# STM32G473 register map
File version: 2.8
CPU: CM4 r0p1, little endian, MPU, FPU, 4 interrupt priority bits
Registers are 32-bit, read-write, reset 0x0 unless marked. A register's access mark holds for its fields unless they carry their own. Offsets are from the block's base; [hi:lo] are bit positions; {n}, {i} and the like mark numbered series; 'fields as' and 'values as' point back to an identical list.

## RCC — Reset and clock control
Base 0x40021000
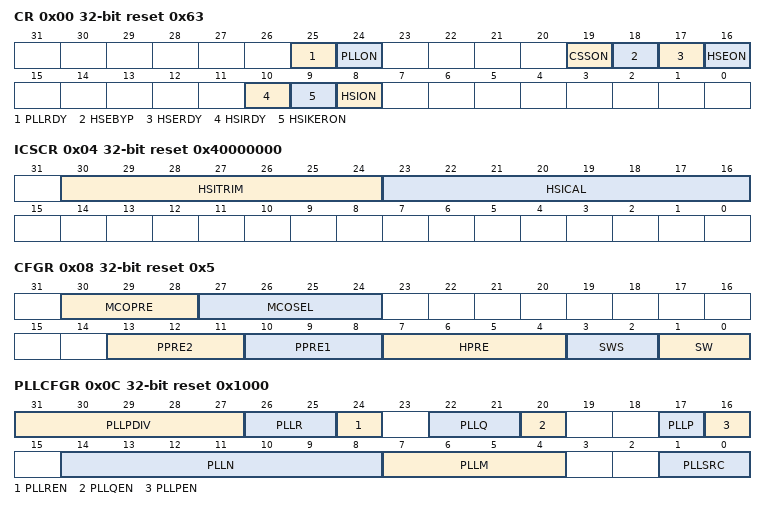
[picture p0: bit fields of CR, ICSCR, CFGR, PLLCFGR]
0x00 CR access per field reset 0x63 — Clock control register
  [25] PLLRDY ro — Main PLL clock ready flag
    0=NotReady (Clock not ready); 1=Ready (Clock ready)
  [24] PLLON rw — Main PLL enable
    0=Off (Clock Off); 1=On (Clock On)
  [19] CSSON rw — Clock security system enable
    0=Off (Clock security system disabled (clock detector OFF)); 1=On (Clock security system enable (clock detector ON if the HSE is ready, OFF if not))
  [18] HSEBYP rw — HSE crystal oscillator bypass
    0=NotBypassed (HSE crystal oscillator not bypassed); 1=Bypassed (HSE crystal oscillator bypassed with external clock)
  [17] HSERDY ro — HSE clock ready flag
    0=NotReady (Clock not ready); 1=Ready (Clock ready)
  [16] HSEON rw — HSE clock enable
    0=Off (Clock Off); 1=On (Clock On)
  [10] HSIRDY ro — HSI16 clock ready flag
    0=NotReady (Clock not ready); 1=Ready (Clock ready)
  [9] HSIKERON rw — HSI16 always enable for peripheral kernels.
  [8] HSION rw — HSI16 clock enable
    0=Off (Clock Off); 1=On (Clock On)
0x04 ICSCR access per field reset 0x40000000 — Internal clock sources calibration register
  [30:24] HSITRIM rw — HSI16 clock trimming
  [23:16] HSICAL ro — HSI16 clock calibration
0x08 CFGR access per field reset 0x5 — Clock configuration register
  [30:28] MCOPRE rw — Microcontroller clock output prescaler
    0=Div1 (MCO divided by 1); 1=Div2 (MCO divided by 2); 2=Div4 (MCO divided by 4); 3=Div8 (MCO divided by 8); 4=Div16 (MCO divided by 16)
  [27:24] MCOSEL rw — Microcontroller clock output
    0=None (MCO output disabled, no clock on MCO); 1=SYSCLK (SYSCLK system clock selected); 2=MSI (MSI clock selected); 3=HSI (HSI clock selected); 4=HSE (HSE clock selected); 5=PLL (Main PLL clock selected); 6=LSI (LSI clock selected); 7=LSE (LSE clock selected); 8=HSI48 (Internal HSI48 clock selected)
  [13:11] PPRE2 rw — APB2 prescaler
    4=Div2 (HCLK divided by 2); 5=Div4 (HCLK divided by 4); 6=Div8 (HCLK divided by 8); 7=Div16 (HCLK divided by 16); other=Div1 (HCLK not divided)
  [10:8] PPRE1 rw — APB1 prescaler
    values as PPRE2
  [7:4] HPRE rw — AHB prescaler
    8=Div2 (SYSCLK divided by 2); 9=Div4 (SYSCLK divided by 4); 10=Div8 (SYSCLK divided by 8); 11=Div16 (SYSCLK divided by 16); 12=Div64 (SYSCLK divided by 64); 13=Div128 (SYSCLK divided by 128); 14=Div256 (SYSCLK divided by 256); 15=Div512 (SYSCLK divided by 512); other=Div1 (SYSCLK not divided)
  [3:2] SWS ro — System clock switch status
    0=MSI (MSI oscillator used as system clock); 1=HSI (HSI oscillator used as system clock); 2=HSE (HSE used as system clock); 3=PLL (PLL used as system clock)
  [1:0] SW rw — System clock switch
    0=MSI (MSI selected as system clock); 1=HSI (HSI selected as system clock); 2=HSE (HSE selected as system clock); 3=PLL (PLL selected as system clock)
0x0C PLLCFGR reset 0x1000 — PLL configuration register
  [31:27] PLLPDIV — Main PLLP division factor
    0=PLLP (pll_p_ck is controlled by PLLP); {v}=Div{v} (pll_p_ck = vco_ck / {v}) (v=2..31)
  [26:25] PLLR — Main PLL division factor for PLL R clock (system clock)
    0=Div2 (pll_r_ck = vco_ck / 2); 1=Div4 (pll_r_ck = vco_ck / 4); 2=Div6 (pll_r_ck = vco_ck / 6); 3=Div8 (pll_r_ck = vco_ck / 8)
  [24] PLLREN — PLL R clock output enable
  [22:21] PLLQ — Main PLL division factor for PLL Q clock.
    0=Div2 (pll_q_ck = vco_ck / 2); 1=Div4 (pll_q_ck = vco_ck / 4); 2=Div6 (pll_q_ck = vco_ck / 6); 3=Div8 (pll_q_ck = vco_ck / 8)
  [20] PLLQEN — Main PLL Q clock output enable
  [17] PLLP — Main PLL division factor for PLL P clock.
    0=Div7 (pll_p_ck = vco_ck / 7); 1=Div17 (pll_p_ck = vco_ck / 17)
  [16] PLLPEN — Main PLL PLL P clock output enable
  [14:8] PLLN — Main PLL multiplication factor for VCO
    {v}=Div{v} (pll_n_ck = vco_ck / {v}) (v=8..127)
  [7:4] PLLM — Division factor for the main PLL input clock
    {v}=Div{v+1} (pll_p_ck = vco_ck / {v+1}) (v=0..15)
  [1:0] PLLSRC — Main PLL entry clock source
    0=None (No clock sent to PLL); 2=HSI16 (HSI16 sent to PLL input); 3=HSE (HSE sent to PLL input)
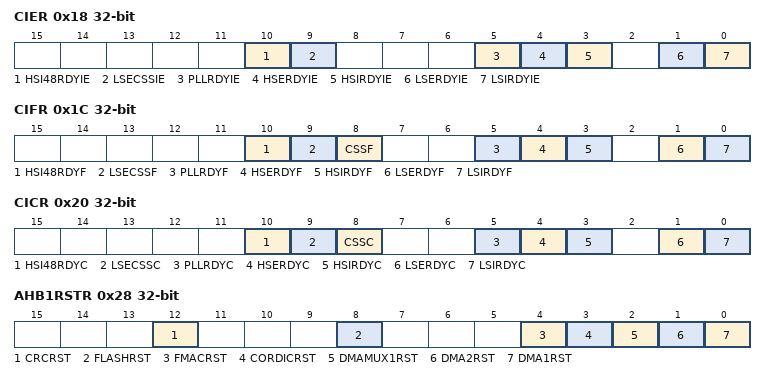
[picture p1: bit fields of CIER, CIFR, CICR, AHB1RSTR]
0x18 CIER — Clock interrupt enable register
  [10] HSI48RDYIE — HSI48 ready interrupt enable
  [9] LSECSSIE — LSE clock security system interrupt enable
  [5] PLLRDYIE — PLL ready interrupt enable
  [4] HSERDYIE — HSE ready interrupt enable
  [3] HSIRDYIE — HSI16 ready interrupt enable
  [1] LSERDYIE — LSE ready interrupt enable
  [0] LSIRDYIE — LSI ready interrupt enable
0x1C CIFR ro — Clock interrupt flag register
  [10] HSI48RDYF — HSI48 ready interrupt flag
  [9] LSECSSF — LSE Clock security system interrupt flag
  [8] CSSF — Clock security system interrupt flag
  [5] PLLRDYF — PLL ready interrupt flag
  [4] HSERDYF — HSE ready interrupt flag
  [3] HSIRDYF — HSI16 ready interrupt flag
  [1] LSERDYF — LSE ready interrupt flag
  [0] LSIRDYF — LSI ready interrupt flag
0x20 CICR wo — Clock interrupt clear register
  [10] HSI48RDYC — HSI48 oscillator ready interrupt clear
  [9] LSECSSC — LSE Clock security system interrupt clear
  [8] CSSC — Clock security system interrupt clear
  [5] PLLRDYC — PLL ready interrupt clear
  [4] HSERDYC — HSE ready interrupt clear
  [3] HSIRDYC — HSI16 ready interrupt clear
  [1] LSERDYC — LSE ready interrupt clear
  [0] LSIRDYC — LSI ready interrupt clear
0x28 AHB1RSTR — AHB1 peripheral reset register
  [all] fields
    1=Reset the selected module
  [12] CRCRST — CRC reset
  [8] FLASHRST — Flash memory interface reset
  [4] FMACRST — Set and cleared by software
  [3] CORDICRST — Set and cleared by software
  [2] DMAMUX1RST — Set and cleared by software.
  [1] DMA2RST — DMA2 reset
  [0] DMA1RST — DMA1 reset
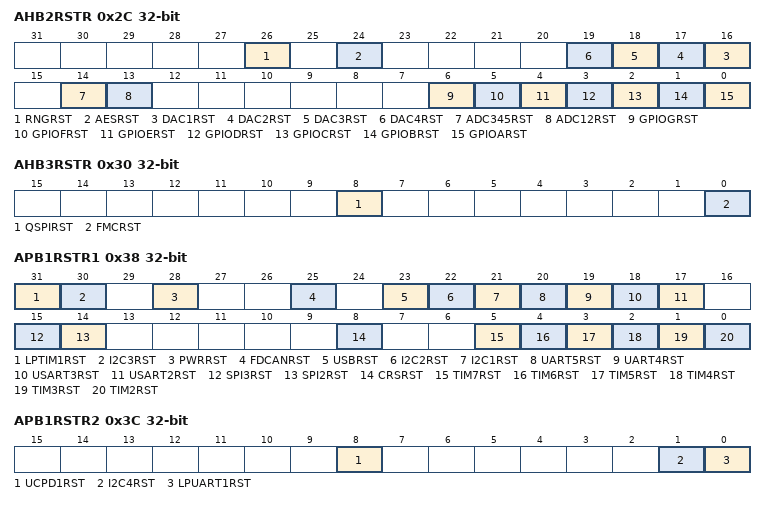
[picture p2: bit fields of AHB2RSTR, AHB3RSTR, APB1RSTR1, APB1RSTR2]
0x2C AHB2RSTR — AHB2 peripheral reset register
  [all] fields
    1=Reset the selected module
  [26] RNGRST — RNG reset
  [24] AESRST — AESRST reset
  [n+15] DAC{n}RST (n=1..4) — DAC{n} reset
  [14] ADC345RST — ADC345 reset
  [13] ADC12RST — ADC12 reset
  [6] GPIOGRST — IO port G reset
  [5] GPIOFRST — IO port F reset
  [4] GPIOERST — IO port E reset
  [3] GPIODRST — IO port D reset
  [2] GPIOCRST — IO port C reset
  [1] GPIOBRST — IO port B reset
  [0] GPIOARST — IO port A reset
0x30 AHB3RSTR — AHB3 peripheral reset register
  [8] QSPIRST — QUADSPI reset
    1=Reset the selected module
  [0] FMCRST — Flexible static memory controller reset
    1=Reset the selected module
0x38 APB1RSTR1 — APB1 peripheral reset register 1
  [all] fields
    1=Reset the selected module
  [31] LPTIM1RST — Low Power Timer 1 reset
  [30] I2C3RST — I2C3 reset
  [28] PWRRST — Power interface reset
  [25] FDCANRST — FDCAN reset
  [23] USBRST — USB device reset
  [22] I2C2RST — I2C2 reset
  [21] I2C1RST — I2C1 reset
  [20] UART5RST — UART5 reset
  [19] UART4RST — UART4 reset
  [18] USART3RST — USART3 reset
  [17] USART2RST — USART2 reset
  [15] SPI3RST — SPI3 reset
  [14] SPI2RST — SPI2 reset
  [8] CRSRST — CRS reset
  [5] TIM7RST — TIM7 timer reset
  [4] TIM6RST — TIM6 timer reset
  [3] TIM5RST — TIM5 timer reset
  [2] TIM4RST — TIM3 timer reset
  [1] TIM3RST — TIM3 timer reset
  [0] TIM2RST — TIM2 timer reset
0x3C APB1RSTR2 — APB1 peripheral reset register 2
  [all] fields
    1=Reset the selected module
  [8] UCPD1RST — UCPD1 reset
  [1] I2C4RST — I2C4 reset
  [0] LPUART1RST — Low-power UART 1 reset
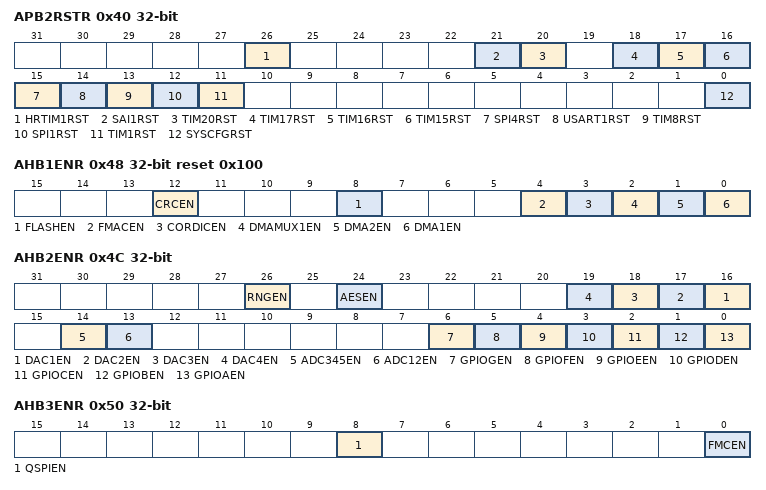
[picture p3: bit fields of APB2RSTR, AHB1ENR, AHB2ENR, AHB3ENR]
0x40 APB2RSTR — APB2 peripheral reset register
  [all] fields
    1=Reset the selected module
  [26] HRTIM1RST — HRTIM1 reset
  [21] SAI1RST — Serial audio interface 1 (SAI1) reset
  [20] TIM20RST — TIM20 reset
  [18] TIM17RST — TIM17 timer reset
  [17] TIM16RST — TIM16 timer reset
  [16] TIM15RST — TIM15 timer reset
  [15] SPI4RST — SPI4 reset
  [14] USART1RST — USART1 reset
  [13] TIM8RST — TIM8 timer reset
  [12] SPI1RST — SPI1 reset
  [11] TIM1RST — TIM1 timer reset
  [0] SYSCFGRST — SYSCFG + COMP + OPAMP + VREFBUF reset
0x48 AHB1ENR reset 0x100 — AHB1 peripheral clock enable register
  [all] fields
    0=Disabled (The selected clock is disabled); 1=Enabled (The selected clock is enabled)
  [12] CRCEN — CRC clock enable
  [8] FLASHEN — Flash memory interface clock enable
  [4] FMACEN — FMAC enable
  [3] CORDICEN — CORDIC clock enable
  [2] DMAMUX1EN — DMAMUX1 clock enable
  [1] DMA2EN — DMA2 clock enable
  [0] DMA1EN — DMA1 clock enable
0x4C AHB2ENR — AHB2 peripheral clock enable register
  [all] fields
    values as the fields of AHB1ENR
  [26] RNGEN — RNG enable
  [24] AESEN — AES clock enable
  [n+15] DAC{n}EN (n=1..4) — DAC{n} clock enable
  [14] ADC345EN — ADC345 clock enable
  [13] ADC12EN — ADC12 clock enable
  [6] GPIOGEN — IO port G clock enable
  [5] GPIOFEN — IO port F clock enable
  [4] GPIOEEN — IO port E clock enable
  [3] GPIODEN — IO port D clock enable
  [2] GPIOCEN — IO port C clock enable
  [1] GPIOBEN — IO port B clock enable
  [0] GPIOAEN — IO port A clock enable
0x50 AHB3ENR — AHB3 peripheral clock enable register
  [8] QSPIEN — QUADSPI memory interface clock enable
    values as the fields of AHB1ENR
  [0] FMCEN — Flexible static memory controller clock enable
    values as the fields of AHB1ENR
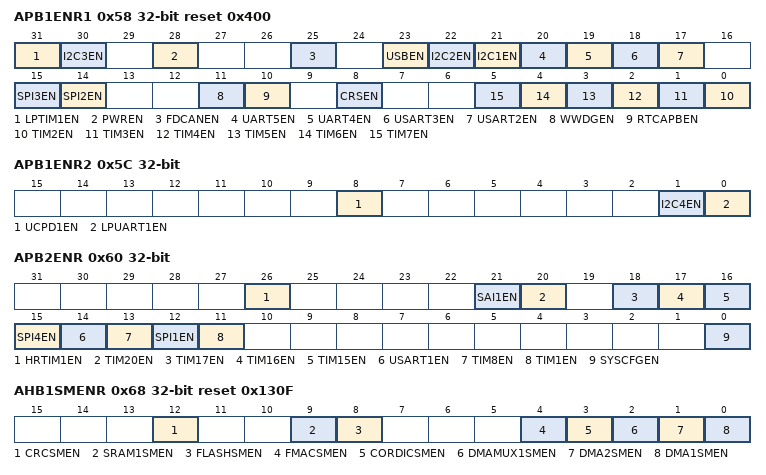
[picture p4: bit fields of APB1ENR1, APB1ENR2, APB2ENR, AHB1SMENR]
0x58 APB1ENR1 reset 0x400 — APB1 peripheral clock enable register 1
  [all] fields
    values as the fields of AHB1ENR
  [31] LPTIM1EN — Low power timer 1 clock enable
  [30] I2C3EN — I2C3 clock enable
  [28] PWREN — Power interface clock enable
  [25] FDCANEN — FDCAN clock enable
  [23] USBEN — USB device clock enable
  [22] I2C2EN — I2C2 clock enable
  [21] I2C1EN — I2C1 clock enable
  [20] UART5EN — UART5 clock enable
  [19] UART4EN — UART4 clock enable
  [18] USART3EN — USART3 clock enable
  [17] USART2EN — USART2 clock enable
  [15] SPI3EN — SPI3 clock enable
  [14] SPI2EN — SPI2 clock enable
  [11] WWDGEN — Window watchdog clock enable
  [10] RTCAPBEN — RTC APB clock enable
  [8] CRSEN — CRS Recovery System clock enable
  [n-2] TIM{n}EN (n=2..7) — TIM{n} timer clock enable
0x5C APB1ENR2 — APB1 peripheral clock enable register 2
  [all] fields
    values as the fields of AHB1ENR
  [8] UCPD1EN — UCPD1 clock enable
  [1] I2C4EN — I2C4 clock enable
  [0] LPUART1EN — Low power UART 1 clock enable
0x60 APB2ENR — APB2 peripheral clock enable register
  [all] fields
    values as the fields of AHB1ENR
  [26] HRTIM1EN — HRTIM1 clock enable
  [21] SAI1EN — SAI1 clock enable
  [20] TIM20EN — TIM20 timer clock enable
  [18] TIM17EN — TIM17 timer clock enable
  [17] TIM16EN — TIM16 timer clock enable
  [16] TIM15EN — TIM15 timer clock enable
  [15] SPI4EN — SPI4 clock enable
  [14] USART1EN — USART1clock enable
  [13] TIM8EN — TIM8 timer clock enable
  [12] SPI1EN — SPI1 clock enable
  [11] TIM1EN — TIM1 timer clock enable
  [0] SYSCFGEN — SYSCFG + COMP + VREFBUF + OPAMP clock enable
0x68 AHB1SMENR reset 0x130F — AHB1 peripheral clocks enable in Sleep and Stop modes register
  [12] CRCSMEN — CRC clocks enable during Sleep and Stop modes
  [9] SRAM1SMEN — SRAM1 interface clocks enable during Sleep and Stop modes
  [8] FLASHSMEN — Flash memory interface clocks enable during Sleep and Stop modes
  [4] FMACSMEN — FMACSM clock enable.
  [3] CORDICSMEN — CORDICSM clock enable.
  [2] DMAMUX1SMEN — DMAMUX1 clock enable during Sleep and Stop modes.
  [1] DMA2SMEN — DMA2 clocks enable during Sleep and Stop modes
  [0] DMA1SMEN — DMA1 clocks enable during Sleep and Stop modes
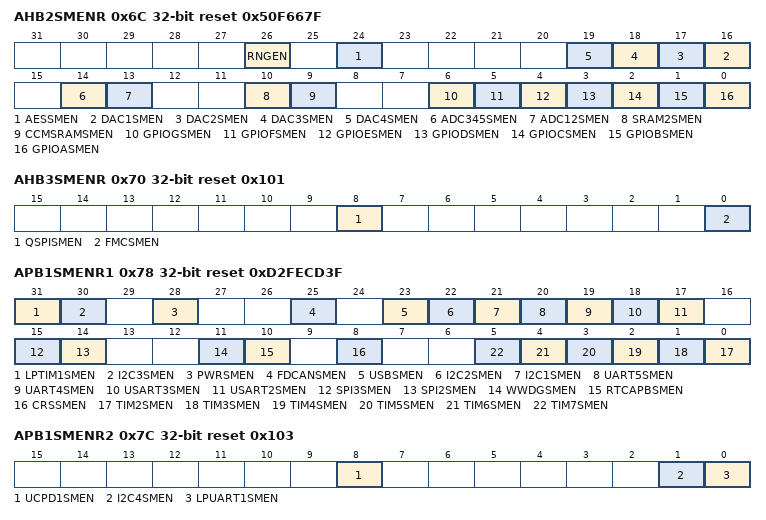
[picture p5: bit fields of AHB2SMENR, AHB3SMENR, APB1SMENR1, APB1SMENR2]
0x6C AHB2SMENR reset 0x50F667F — AHB2 peripheral clocks enable in Sleep and Stop modes register
  [26] RNGEN — RNG enable
  [24] AESSMEN — AESM clocks enable
  [n+15] DAC{n}SMEN (n=1..4) — DAC{n} clock enable
  [14] ADC345SMEN — ADC345 clock enable
  [13] ADC12SMEN — ADC12 clocks enable during Sleep and Stop modes
  [10] SRAM2SMEN — SRAM2 interface clocks enable during Sleep and Stop modes
  [9] CCMSRAMSMEN — CCM SRAM interface clocks enable during Sleep and Stop modes
  [6] GPIOGSMEN — IO port G clocks enable during Sleep and Stop modes
  [5] GPIOFSMEN — IO port F clocks enable during Sleep and Stop modes
  [4] GPIOESMEN — IO port E clocks enable during Sleep and Stop modes
  [3] GPIODSMEN — IO port D clocks enable during Sleep and Stop modes
  [2] GPIOCSMEN — IO port C clocks enable during Sleep and Stop modes
  [1] GPIOBSMEN — IO port B clocks enable during Sleep and Stop modes
  [0] GPIOASMEN — IO port A clocks enable during Sleep and Stop modes
0x70 AHB3SMENR reset 0x101 — AHB3 peripheral clocks enable in Sleep and Stop modes register
  [8] QSPISMEN — QUADSPI memory interface clock enable during Sleep and Stop modes
  [0] FMCSMEN — Flexible static memory controller clocks enable during Sleep and Stop modes
0x78 APB1SMENR1 reset 0xD2FECD3F — APB1 peripheral clocks enable in Sleep and Stop modes register 1
  [31] LPTIM1SMEN — Low power timer 1 clocks enable during Sleep and Stop modes
  [30] I2C3SMEN — I2C3 clocks enable during Sleep and Stop modes
  [28] PWRSMEN — Power interface clocks enable during Sleep and Stop modes
  [25] FDCANSMEN — FDCAN clocks enable during Sleep and Stop modes
  [23] USBSMEN — USB device clocks enable during Sleep and Stop modes
  [22] I2C2SMEN — I2C2 clocks enable during Sleep and Stop modes
  [21] I2C1SMEN — I2C1 clocks enable during Sleep and Stop modes
  [20] UART5SMEN — UART5 clocks enable during Sleep and Stop modes
  [19] UART4SMEN — UART4 clocks enable during Sleep and Stop modes
  [18] USART3SMEN — USART3 clocks enable during Sleep and Stop modes
  [17] USART2SMEN — USART2 clocks enable during Sleep and Stop modes
  [15] SPI3SMEN — SPI3 clocks enable during Sleep and Stop modes
  [14] SPI2SMEN — SPI2 clocks enable during Sleep and Stop modes
  [11] WWDGSMEN — Window watchdog clocks enable during Sleep and Stop modes
  [10] RTCAPBSMEN — RTC APB clock enable during Sleep and Stop modes
  [8] CRSSMEN — CRS timer clocks enable during Sleep and Stop modes
  [n-2] TIM{n}SMEN (n=2..7) — TIM{n} timer clocks enable during Sleep and Stop modes
0x7C APB1SMENR2 reset 0x103 — APB1 peripheral clocks enable in Sleep and Stop modes register 2
  [8] UCPD1SMEN — UCPD1 clocks enable during Sleep and Stop modes
  [1] I2C4SMEN — I2C4 clocks enable during Sleep and Stop modes
  [0] LPUART1SMEN — Low power UART 1 clocks enable during Sleep and Stop modes
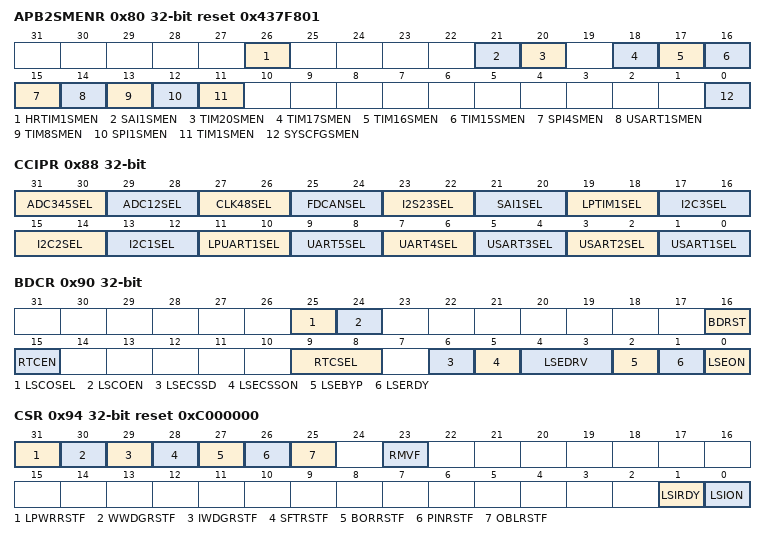
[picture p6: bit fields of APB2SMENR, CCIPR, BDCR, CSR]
0x80 APB2SMENR reset 0x437F801 — APB2 peripheral clocks enable in Sleep and Stop modes register
  [26] HRTIM1SMEN — HRTIM1 timer clocks enable during Sleep and Stop modes
  [21] SAI1SMEN — SAI1 clocks enable during Sleep and Stop modes
  [20] TIM20SMEN — TIM20 timer clocks enable during Sleep and Stop modes
  [18] TIM17SMEN — TIM17 timer clocks enable during Sleep and Stop modes
  [17] TIM16SMEN — TIM16 timer clocks enable during Sleep and Stop modes
  [16] TIM15SMEN — TIM15 timer clocks enable during Sleep and Stop modes
  [15] SPI4SMEN — SPI4 timer clocks enable during Sleep and Stop modes
  [14] USART1SMEN — USART1clocks enable during Sleep and Stop modes
  [13] TIM8SMEN — TIM8 timer clocks enable during Sleep and Stop modes
  [12] SPI1SMEN — SPI1 clocks enable during Sleep and Stop modes
  [11] TIM1SMEN — TIM1 timer clocks enable during Sleep and Stop modes
  [0] SYSCFGSMEN — SYSCFG + COMP + VREFBUF + OPAMP clocks enable during Sleep and Stop modes
0x88 CCIPR — Peripherals independent clock configuration register
  [31:30] ADC345SEL — ADC3/4/5 clock source selection
    0=None (No clock selected for ADC); 1=PLLP (PLL 'P' clock selected for ADC); 2=System clock selected for ADC
  [29:28] ADC12SEL — ADC1/2 clock source selection
    values as ADC345SEL
  [27:26] CLK48SEL — 48 MHz clock source selection
    0=HSI48 (HSI48 clock selected as 48MHz clock); 2=PLLQ (PLL 'Q' (PLL48M1CLK) clock selected as 48MHz clock)
  [25:24] FDCANSEL
    0=HSE (HSE clock selected as FDCAN clock); 1=PLLQ (PLL 'Q' clock selected as FDCAN clock); 2=PCLK (PCLK clock selected as FDCAN clock)
  [23:22] I2S23SEL — clock source selection
    0=System clock selected as I2S23 clock; 1=PLLQ (PLL 'Q' clock selected as I2S23 clock); 2=I2S_CKIN (Clock provided on I2S_CKIN pin is selected as I2S23 clock); 3=HSI16 (HSI16 clock selected as I2S23 clock)
  [21:20] SAI1SEL — clock source selection
    0=System clock selected as SAI clock; 1=PLLQ (PLL 'Q' clock selected as SAI clock); 2=I2S_CKIN (Clock provided on I2S_CKIN pin is selected as SAI clock); 3=HSI16 (HSI16 clock selected as SAI clock)
  [19:18] LPTIM1SEL — Low power timer 1 clock source selection
    0=PCLK (PCLK clock selected as LPTIM1 clock); 1=LSI (LSI clock selected as LPTIM1 clock); 2=HSI16 (HSI16 clock selected as LPTIM1 clock); 3=LSE (LSE clock selected as LPTIM1 clock)
  [17:16] I2C3SEL — I2C3 clock source selection
    0=PCLK (PCLK clock selected as I2C clock); 1=System clock (SYSCLK) selected as I2C clock; 2=HSI16 (HSI16 clock selected as I2C clock)
  [15:14] I2C2SEL — I2C2 clock source selection
    values as I2C3SEL
  [13:12] I2C1SEL — I2C1 clock source selection
    values as I2C3SEL
  [11:10] LPUART1SEL — LPUART1 clock source selection
    0=PCLK (PCLK clock selected as UART clock); 1=System clock (SYSCLK) selected as UART clock; 2=HSI16 (HSI16 clock selected as UART clock); 3=LSE (LSE clock selected as UART clock)
  [9:8] UART5SEL — UART5 clock source selection
    values as LPUART1SEL
  [7:6] UART4SEL — UART4 clock source selection
    values as LPUART1SEL
  [5:4] USART3SEL — USART3 clock source selection
  [3:2] USART2SEL — USART2 clock source selection
  [1:0] USART1SEL — USART1 clock source selection
0x90 BDCR access per field — RTC domain control register
  [25] LSCOSEL rw — Low speed clock output selection
    0=LSI (LSI clock selected); 1=LSE (LSE clock selected)
  [24] LSCOEN rw — Low speed clock output enable
    0=Disabled (LSCO disabled); 1=Enabled (LSCO enabled)
  [16] BDRST rw — RTC domain software reset
    0=Disabled (Reset not activated); 1=Enabled (Reset the entire RTC domain)
  [15] RTCEN rw — RTC clock enable
    0=Disabled (RTC clock disabled); 1=Enabled (RTC clock enabled)
  [9:8] RTCSEL rw — RTC clock source selection
    0=NoClock; 1=LSE (LSE oscillator clock used as RTC clock); 2=LSI (LSI oscillator clock used as RTC clock); 3=HSE (HSE oscillator clock divided by a prescaler used as RTC clock)
  [6] LSECSSD ro — CSS on LSE failure Detection
    0=No failure detected on LSE (32 kHz oscillator); 1=Failure detected on LSE (32 kHz oscillator)
  [5] LSECSSON rw — CSS on LSE enable
    0=Off (CSS on LSE (32 kHz external oscillator) OFF); 1=On (CSS on LSE (32 kHz external oscillator) ON)
  [4:3] LSEDRV rw — LSE oscillator drive capability
    0=Lower ('Xtal mode' lower driving capability); 1=MediumLow ('Xtal mode' medium low driving capability); 2=MediumHigh ('Xtal mode' medium high driving capability); 3=Higher ('Xtal mode' higher driving capability)
  [2] LSEBYP rw — LSE oscillator bypass
    0=NotBypassed (LSE crystal oscillator not bypassed); 1=Bypassed (LSE crystal oscillator bypassed with external clock)
  [1] LSERDY ro — LSE oscillator ready
    0=NotReady (LSE clock not ready); 1=Ready (LSE clock ready)
  [0] LSEON rw — LSE oscillator enable
    0=Off (LSE only enabled when requested by a peripheral or system function); 1=On (LSE enabled always generated by RCC)
0x94 CSR access per field reset 0xC000000 — Control/status register
  [31] LPWRRSTF ro — Low-power reset flag
    0=No reset has occured; 1=Reset (A reset has occured)
  [30] WWDGRSTF ro — Window watchdog reset flag
    0=No reset has occured; 1=Reset (A reset has occured)
  [29] IWDGRSTF ro — Independent window watchdog reset flag
    0=No reset has occured; 1=Reset (A reset has occured)
  [28] SFTRSTF ro — Software reset flag
    0=No reset has occured; 1=Reset (A reset has occured)
  [27] BORRSTF ro — BOR flag
    0=No reset has occured; 1=Reset (A reset has occured)
  [26] PINRSTF ro — Pin reset flag
    0=No reset has occured; 1=Reset (A reset has occured)
  [25] OBLRSTF ro — Option byte loader reset flag
    0=No reset has occured; 1=Reset (A reset has occured)
  [23] RMVF rw — Remove reset flag
    on write: 1=Clears the reset flag
  [1] LSIRDY ro — LSI oscillator ready
    0=NotReady (LSI oscillator not ready); 1=Ready (LSI oscillator ready)
  [0] LSION rw — LSI oscillator enable
    0=Off (LSI oscillator Off); 1=On (LSI oscillator On)
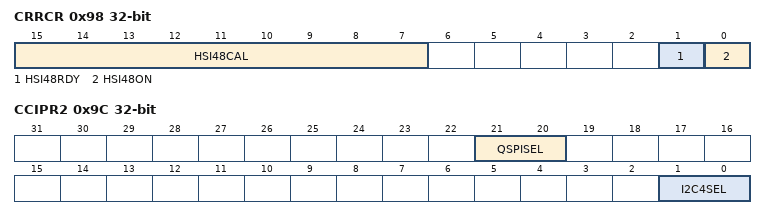
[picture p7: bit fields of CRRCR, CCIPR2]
0x98 CRRCR access per field — Clock recovery RC register
  [15:7] HSI48CAL ro — HSI48 clock calibration
  [1] HSI48RDY ro — HSI48 clock ready flag
  [0] HSI48ON rw — HSI48 clock enable
0x9C CCIPR2 — Peripherals independent clock configuration register
  [21:20] QSPISEL — QUADSPI clock source selection
    0=System clock selected as QUADSPI kernel clock; 1=HSI16 (HSI16 clock selected as QUADSPI kernel clock); 2=PLLQ (PLL 'Q' clock selected as QUADSPI kernel clock)
  [1:0] I2C4SEL — I2C4 clock source selection
    values as CCIPR.I2C3SEL
